# AT91SAM9M10 register map
Vendor: Atmel; File version: 20130207
CPU: 
Registers are 32-bit, read-write, no defined reset value unless marked. A register's access mark holds for its fields unless they carry their own. Offsets are from the block's base; [hi:lo] are bit positions; {n}, {i} and the like mark numbered series; 'fields as' and 'values as' point back to an identical list.

## RSTC — Reset Controller
Base 0xFFFFFD00; register names take the prefix RSTC_
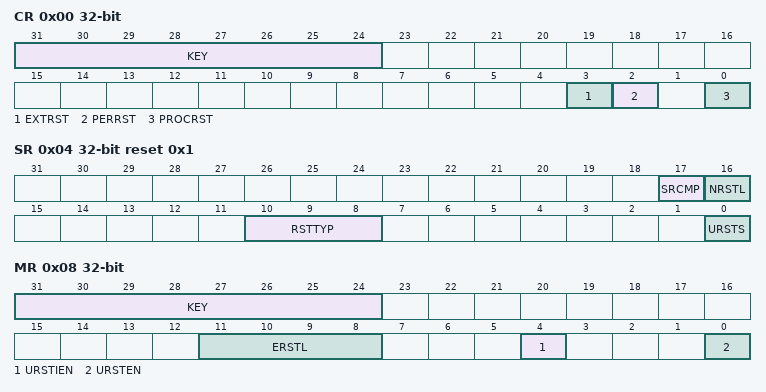
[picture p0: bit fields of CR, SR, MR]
0x00 CR wo — Control Register
  [31:24] KEY — Password
  [3] EXTRST — External Reset
  [2] PERRST — Peripheral Reset
  [0] PROCRST — Processor Reset
0x04 SR ro reset 0x1 — Status Register
  [17] SRCMP — Software Reset Command in Progress
  [16] NRSTL — NRST Pin Level
  [10:8] RSTTYP — Reset Type
  [0] URSTS — User Reset Status
0x08 MR — Mode Register
  [31:24] KEY — Password
  [11:8] ERSTL — External Reset Length
  [4] URSTIEN — User Reset Interrupt Enable
  [0] URSTEN — User Reset Enable

## SHDWC — Shutdown Controller
Base 0xFFFFFD10; register names take the prefix SHDWC_
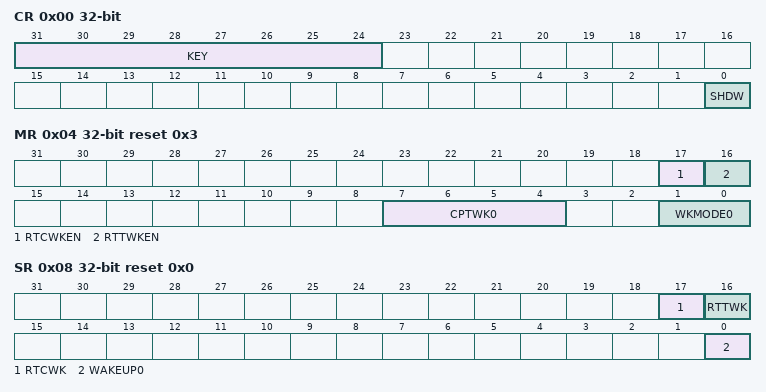
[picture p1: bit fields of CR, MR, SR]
0x00 CR wo — Shutdown Control Register
  [31:24] KEY — Password
  [0] SHDW — Shutdown Command
0x04 MR reset 0x3 — Shutdown Mode Register
  [17] RTCWKEN — Real-time Clock Wake-up Enable
  [16] RTTWKEN — Real-time Timer Wake-up Enable
  [7:4] CPTWK0 — Counter on Wake-up 0
  [1:0] WKMODE0 — Wake-up Mode 0
0x08 SR ro reset 0x0 — Shutdown Status Register
  [17] RTCWK — Real-time Clock Wake-up
  [16] RTTWK — Real-time Timer Wake-up
  [0] WAKEUP0 — Wake-up 0 Status

## RTT — Real-time Timer
Base 0xFFFFFD20; register names take the prefix RTT_
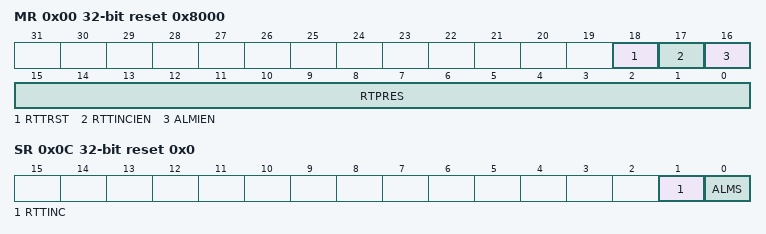
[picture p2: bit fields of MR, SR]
0x00 MR reset 0x8000 — Mode Register
  [18] RTTRST — Real-time Timer Restart
  [17] RTTINCIEN — Real-time Timer Increment Interrupt Enable
  [16] ALMIEN — Alarm Interrupt Enable
  [15:0] RTPRES — Real-time Timer Prescaler Value
0x04 AR reset 0xFFFFFFFF — Alarm Register
  [31:0] ALMV — Alarm Value
0x08 VR ro reset 0x0 — Value Register
  [31:0] CRTV — Current Real-time Value
0x0C SR ro reset 0x0 — Status Register
  [1] RTTINC — Real-time Timer Increment
  [0] ALMS — Real-time Alarm Status

## PIT — Periodic Interval Timer
Base 0xFFFFFD30; register names take the prefix PIT_
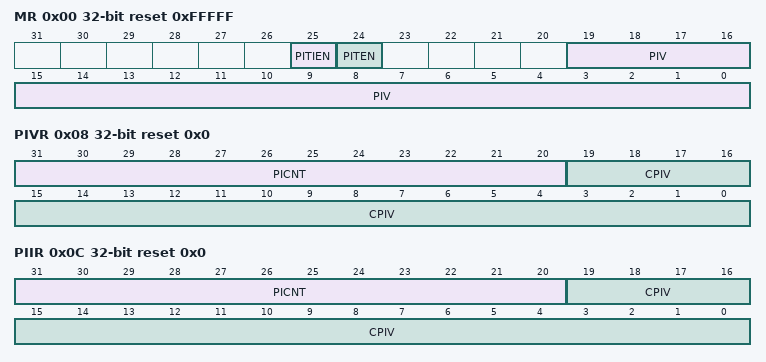
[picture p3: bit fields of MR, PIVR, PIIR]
0x00 MR reset 0xFFFFF — Mode Register
  [25] PITIEN — Periodic Interval Timer Interrupt Enable
  [24] PITEN — Period Interval Timer Enabled
  [19:0] PIV — Periodic Interval Value
0x04 SR ro reset 0x0 — Status Register
  [0] PITS — Periodic Interval Timer Status
0x08 PIVR ro reset 0x0 — Periodic Interval Value Register
  [31:20] PICNT — Periodic Interval Counter
  [19:0] CPIV — Current Periodic Interval Value
0x0C PIIR ro reset 0x0 — Periodic Interval Image Register
  fields as PIVR

## WDT — Watchdog Timer
Base 0xFFFFFD40; register names take the prefix WDT_
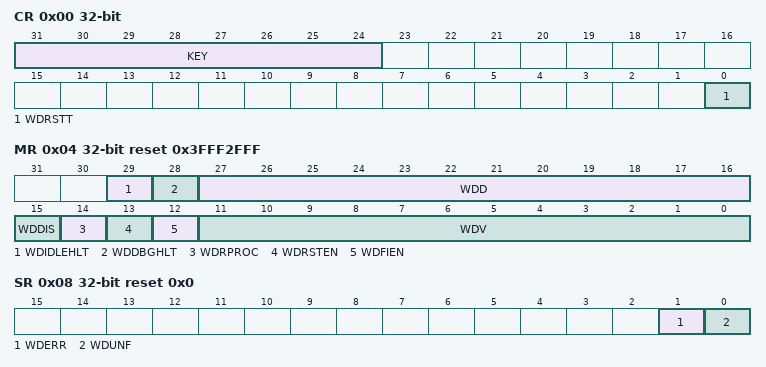
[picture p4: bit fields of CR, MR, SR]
0x00 CR wo — Control Register
  [31:24] KEY — Password
  [0] WDRSTT — Watchdog Restart
0x04 MR reset 0x3FFF2FFF — Mode Register
  [29] WDIDLEHLT — Watchdog Idle Halt
  [28] WDDBGHLT — Watchdog Debug Halt
  [27:16] WDD — Watchdog Delta Value
  [15] WDDIS — Watchdog Disable
  [14] WDRPROC — Watchdog Reset Processor
  [13] WDRSTEN — Watchdog Reset Enable
  [12] WDFIEN — Watchdog Fault Interrupt Enable
  [11:0] WDV — Watchdog Counter Value
0x08 SR ro reset 0x0 — Status Register
  [1] WDERR — Watchdog Error
  [0] WDUNF — Watchdog Underflow

## GPBR — General Purpose Backup Register
Base 0xFFFFFD60; register names take the prefix GPBR_
{0x0+4i} GPBR{i} (i=0..3) — General Purpose Backup Register {i}
  [31:0] GPBR_VALUE{i} — Value of GPBR x

## RTC — Real-time Clock
Base 0xFFFFFDB0; register names take the prefix RTC_
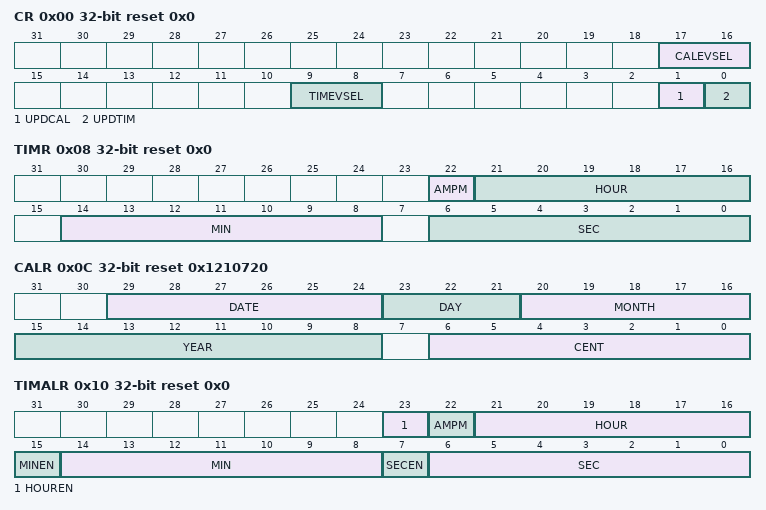
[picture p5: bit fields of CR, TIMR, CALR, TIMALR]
0x00 CR reset 0x0 — Control Register
  [17:16] CALEVSEL — Calendar Event Selection
    0=WEEK (Week change (every Monday at time 00:00:00)); 1=MONTH (Month change (every 01 of each month at time 00:00:00)); 2=YEAR (Year change (every January 1 at time 00:00:00))
  [9:8] TIMEVSEL — Time Event Selection
    0=MINUTE (Minute change); 1=HOUR (Hour change); 2=MIDNIGHT (Every day at midnight); 3=NOON (Every day at noon)
  [1] UPDCAL — Update Request Calendar Register
  [0] UPDTIM — Update Request Time Register
0x04 MR reset 0x0 — Mode Register
  [0] HRMOD — 12-/24-hour Mode
0x08 TIMR reset 0x0 — Time Register
  [22] AMPM — Ante Meridiem Post Meridiem Indicator
  [21:16] HOUR — Current Hour
  [14:8] MIN — Current Minute
  [6:0] SEC — Current Second
0x0C CALR reset 0x1210720 — Calendar Register
  [29:24] DATE — Current Day in Current Month
  [23:21] DAY — Current Day in Current Week
  [20:16] MONTH — Current Month
  [15:8] YEAR — Current Year
  [6:0] CENT — Current Century
0x10 TIMALR reset 0x0 — Time Alarm Register
  [23] HOUREN — Hour Alarm Enable
  [22] AMPM — AM/PM Indicator
  [21:16] HOUR — Hour Alarm
  [15] MINEN — Minute Alarm Enable
  [14:8] MIN — Minute Alarm
  [7] SECEN — Second Alarm Enable
  [6:0] SEC — Second Alarm
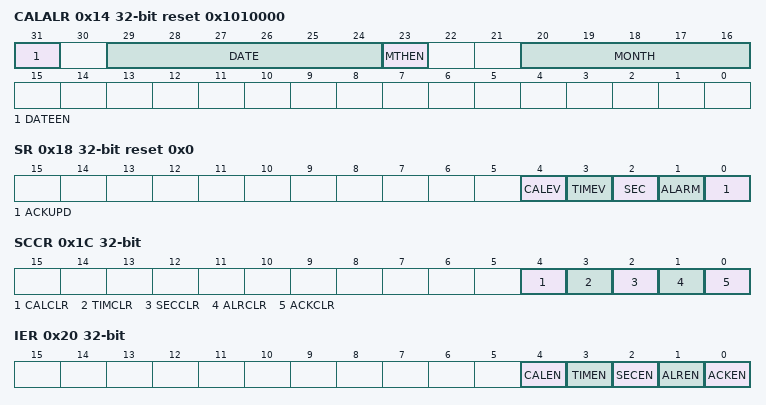
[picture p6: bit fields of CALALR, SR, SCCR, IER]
0x14 CALALR reset 0x1010000 — Calendar Alarm Register
  [31] DATEEN — Date Alarm Enable
  [29:24] DATE — Date Alarm
  [23] MTHEN — Month Alarm Enable
  [20:16] MONTH — Month Alarm
0x18 SR ro reset 0x0 — Status Register
  [4] CALEV — Calendar Event
  [3] TIMEV — Time Event
  [2] SEC — Second Event
  [1] ALARM — Alarm Flag
  [0] ACKUPD — Acknowledge for Update
0x1C SCCR wo — Status Clear Command Register
  [4] CALCLR — Calendar Clear
  [3] TIMCLR — Time Clear
  [2] SECCLR — Second Clear
  [1] ALRCLR — Alarm Clear
  [0] ACKCLR — Acknowledge Clear
0x20 IER wo — Interrupt Enable Register
  [4] CALEN — Calendar Event Interrupt Enable
  [3] TIMEN — Time Event Interrupt Enable
  [2] SECEN — Second Event Interrupt Enable
  [1] ALREN — Alarm Interrupt Enable
  [0] ACKEN — Acknowledge Update Interrupt Enable
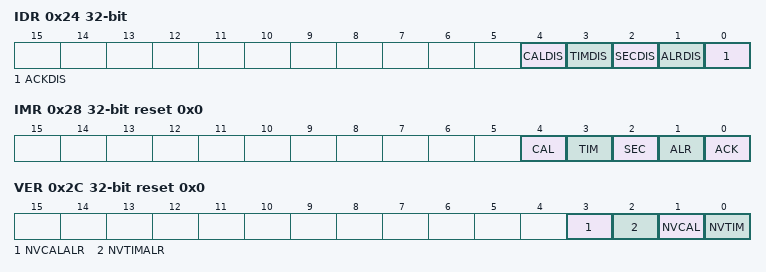
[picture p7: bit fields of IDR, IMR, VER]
0x24 IDR wo — Interrupt Disable Register
  [4] CALDIS — Calendar Event Interrupt Disable
  [3] TIMDIS — Time Event Interrupt Disable
  [2] SECDIS — Second Event Interrupt Disable
  [1] ALRDIS — Alarm Interrupt Disable
  [0] ACKDIS — Acknowledge Update Interrupt Disable
0x28 IMR ro reset 0x0 — Interrupt Mask Register
  [4] CAL — Calendar Event Interrupt Mask
  [3] TIM — Time Event Interrupt Mask
  [2] SEC — Second Event Interrupt Mask
  [1] ALR — Alarm Interrupt Mask
  [0] ACK — Acknowledge Update Interrupt Mask
0x2C VER ro reset 0x0 — Valid Entry Register
  [3] NVCALALR — Non-valid Calendar Alarm
  [2] NVTIMALR — Non-valid Time Alarm
  [1] NVCAL — Non-valid Calendar
  [0] NVTIM — Non-valid Time
